# T113-S3 register map
Vendor: Allwinner; Series: T113-S3; File version: 0.1
CPU: other 0, little endian, MPU, no FPU, 0 interrupt priority bits
Registers are 32-bit, read-write, reset 0x0 unless marked. A register's access mark holds for its fields unless they carry their own. Offsets are from the block's base; [hi:lo] are bit positions; {n}, {i} and the like mark numbered series.

## CAN0
Base 0x02504000
Same registers: CAN1 0x02504400
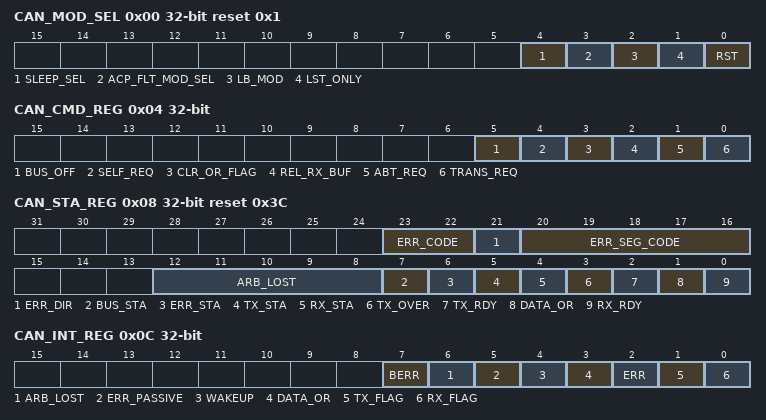
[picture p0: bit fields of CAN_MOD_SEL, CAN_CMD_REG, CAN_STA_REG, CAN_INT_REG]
0x00 CAN_MOD_SEL reset 0x1
  [4] SLEEP_SEL — Sleep Mode 0 : Wake-up (normal operation). If sleeping, the controller wakes up. 1: Sleep. The controller enters its Sleep Mode provided no CAN interrupt is pending and there is no bus activity (If there is bus activity or an interrupt is pending, the Wake-Up procedure is executed). Note: This bit can only be written in Operation Mode.
    1=Sleep. The controller enters its Sleep Mode provided no CAN interrupt is pending and there is no bus activity (If there is bus activity or an interrupt is pending, the Wake-Up procedure is executed). Note: This bit can only be written in Operation Mode.
  [3] ACP_FLT_MOD_SEL — Acceptance Filter Mode Select 0 : Dual Filter. Receive data filtered using two shorter filters. 1: Single Filter. Receive data MOD.3 AFM Acceptance Filter Mode1 filtered using one 4-byte filter.
    1=Single Filter. Receive data MOD.3 AFM Acceptance Filter Mode1 filtered using one 4-byte filter.
  [2] LB_MOD — Loopback Mode 0: Normal operation. An acknowledgement is required for successful transmission. 1: Self Test enabled. In this mode, a full node test is possible without any other active node on the bus using the self reception request command. The MCAN2 will perform a successful transmission, even if no acknowledge is received.
    0=Normal operation. An acknowledgement is required for successful transmission.; 1=Self Test enabled. In this mode, a full node test is possible without any other active node on the bus using the self reception request command. The MCAN2 will perform a successful transmission, even if no acknowledge is received.
  [1] LST_ONLY — Listen Only Mode 0: Normal operation. The error counters are stopped at the current value. 1: Listen Only enabled. In this mode, the controller does not send an acknowledge to the CAN bus, even when a message is received successfully.
    0=Normal operation. The error counters are stopped at the current value.; 1=Listen Only enabled. In this mode, the controller does not send an acknowledge to the CAN bus, even when a message is received successfully.
  [0] RST — Reset Mode 0: Normal operation. The controller returns to Operating Mode 1: Reset mode selected. Any message currently being transmitted or received is aborted and Reset Mode is entered.
    0=Normal operation. The controller returns to Operating Mode; 1=Reset mode selected. Any message currently being transmitted or received is aborted and Reset Mode is entered.
0x04 CAN_CMD_REG
  [5] BUS_OFF wo — Bus off Request Set this bit to 1 to initial a CPU-driven BUS OFF event.
  [4] SELF_REQ wo — Self Reception Request Set this bit to 1 to make a message to be transmitted and received simultaneously.
  [3] CLR_OR_FLAG wo — Clear Data Overrun Flag Set this bit to 1 to clear the data overrun flag signaled by the data overrun status bit. Note: No further data overrun interrupt will be generated while data overrun status bit remains set.
  [2] REL_RX_BUF wo — Release Rx Buffer Set this bit to 1 to release receive buffer.
  [1] ABT_REQ wo — Abort Request Set this bit to 1 to request to abort the current message transmission.
  [0] TRANS_REQ wo — Transmission Request Set this bit to 1 to request to transmit a message.
0x08 CAN_STA_REG reset 0x3C
  [23:22] ERR_CODE ro — Error Capture Error Code 00: Bit error 01: Form error 10: Stuff error 11: Some other type of error
    0=Bit (Bit error); 1=Form error; 2=Stuff error; 3=Some other type of error
  [21] ERR_DIR ro — Error Capture Direction 1: The error occurred during reception. 0 : The error occurred during transmission.
    1=error (The error occurred during reception. 0 : The error occurred during transmission.)
  [20:16] ERR_SEG_CODE ro — Error Capture Segment Code 00011: Start of frame 00010: ID.28 to ID.21 00110: ID.20 to ID.18 00100: SRTR bit 00101: IDE bit 00111: ID.17 to ID.13 01111: ID.12 to ID.5 01110: ID.4 to ID.0 01100: RTR bit 01101: Reserved bit 1 01001: Reserved bit 0 01011: Data Length Code 01010: Data Field 01000: CRC sequence 11000: CRC delimiter 11001: Acknowledge 11011: Acknowledge delimiter 11010: End of frame 10010: Intermission 10001: Active error flag 10110: Passive error flag 10011: Tolerate dominant bits 10111: Error delimiter 11100: Overload flag
  [12:8] ARB_LOST ro — Arbitration Lost Capture 00000~01010: Arbitration lost in bit[0~10](1 ~11 bit of ID, ID.28~ID.18). 01011: Arbitration lost in bit[11](SRTR bit ). 01100: Arbitration lost in bit[12](IDE bit ). 01101~11110: Arbitration lost in bit[13th~30th](12th~29th bit of ID, ID.17~ID.0). 11111: Arbitration lost in bit[31](RTR bit ).
    11=Arbitration_lost_in_bit[11]_openingparen_SRTR_bit (Arbitration lost in bit[11](SRTR bit ).); 12=Arbitration_lost_in_bit[12]_openingparen_IDE_bit (Arbitration lost in bit[12](IDE bit ). 01101~11110: Arbitration lost in bit[13th~30th](12th~29th bit of ID, ID.17~ID.0).); 31=Arbitration_lost_in_bit[31]_openingparen_RTR_bit (Arbitration lost in bit[31](RTR bit ).)
  [7] BUS_STA ro — Bus Status 0: The controller is involved in bus activities. 1: The controller is in `Bus Off` state and is not involved in bus activities.
    0=involved (The controller is involved in bus activities.); 1=in (The controller is in `Bus Off` state and is not involved in bus activities.)
  [6] ERR_STA ro — Error Status 0: Both error counters are below the warning limit. 1: At least one of the error counters has reached or exceeded the CPU warning limit defined by the Error Warning Limit Register (EWL).
    0=Both error counters are below the warning limit; 1=At (At least one of the error counters has reached or exceeded the CPU warning limit defined by the Error Warning Limit Register (EWL).)
  [5] TX_STA ro — Transmit Status 0: Nothing is currently being Transmitted. 1: Controller is in the process of transmitting a message.
    0=Nothing is currently being Transmitted; 1=Controller is in the process of transmitting a message
  [4] RX_STA ro — Receive Status 0: Nothing is currently being received. 1: Controller is in the process of receiving a message.
    0=Nothing is currently being received; 1=Controller is in the process of receiving a message
  [3] TX_OVER ro — Transmission Complete 0: The last requested transmission has not been completed. 1: The last requested transmission has been successfully completed.
    0=last_requested_transmission_has_not_been (The last requested transmission has not been completed.); 1=last_requested_transmission_has_been (The last requested transmission has been successfully completed.)
  [2] TX_RDY ro — Tx Buffer Ready 0: Tx buffer not ready. Transmit buffer is locked. The CPU cannot access the tx buffer. 1: Tx buffer ready. Transmit buffer is released. The CPU may write a message to transmit buffer.
    0=Tx buffer not ready. Transmit buffer is locked. The CPU cannot access the tx buffer.; 1=Tx buffer ready. Transmit buffer is released. The CPU may write a message to transmit buffer.
  [1] DATA_OR ro — Data overrun 0: Data buffer not overrun. 1: Data buffer overrun.
    0=Data_buffer_not_overrun; 1=Data_buffer_overrun
  [0] RX_RDY ro — Rx Buffer Ready 0: Rx buffer is empty. No message currently available to be read. 1: Rx buffer is not empty. One or more message are available to be read from Rx buffer.
    0=empty (Rx buffer is empty. No message currently available to be read.); 1=not_empty (Rx buffer is not empty. One or more message are available to be read from Rx buffer.)
0x0C CAN_INT_REG
  [7] BERR write-1-clears — Bus Error Interrupt Set when the controller detects an bit error on the CAN bus Note: This is a wirte-1-to-clear bit.
  [6] ARB_LOST write-1-clears — Arbitration Lost Interrupt Set when the controller loses arbitration and becomes a receiver Note: This is a wirte-1-to-clear bit.
  [5] ERR_PASSIVE write-1-clears — Error Passive Interrupt Set when the controller re-enters error active state after being in error passive state or when at least one error counter exceeds the protocol-defined level of 127. Note: This is a wirte-1-to-clear bit.
  [4] WAKEUP ro read-clears — Wake-Up Interrupt Set when bus activity is detected while the CAN controller is sleeping This is a read-to-clear bit.
  [3] DATA_OR write-1-clears — Data Overrun Interrupt Set on a `0-to-1` transition of the Data Overrun Status bit Note: This is a wirte-1-to-clear bit.
  [2] ERR write-1-clears — Error Warning Interrupt Set on every change (set or clear) of either the Bus Status or Error Status bits (SR.7,SR.6) Note: This is a wirte-1-to-clear bit.
  [1] TX_FLAG write-1-clears — Transmit Interrupt Flag Set whenever the Transmit Buffer Status (SR.2) changes from `0-to-1` (released) Note: This is a wirte-1-to-clear bit.
  [0] RX_FLAG write-1-clears — Receive Interrupt Flag Set whenever the Receive Buffer contains one or more messages. Cleared when the release Receive Buffer command (CMR. 2) is issued, provided there is no further data to read in the Receive Buffer. Note: This is a wirte-1-to-clear bit.
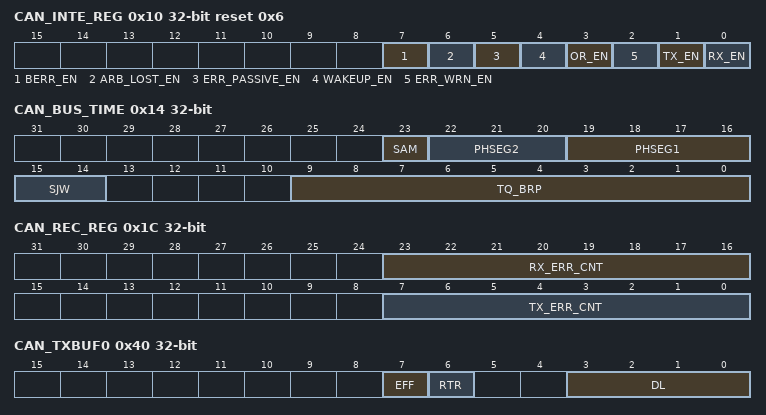
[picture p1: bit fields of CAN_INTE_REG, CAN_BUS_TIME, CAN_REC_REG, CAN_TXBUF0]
0x10 CAN_INTE_REG reset 0x6
  [7] BERR_EN — Bus Error Interrupt Enable 0: Bus error interrupt disable 1: Bus error interrupt enable
    0=Bus_error_interrupt_disable; 1=Bus_error_interrupt_enable
  [6] ARB_LOST_EN — Arbitration Lost Interrupt Enable 0: Arbitration lost interrupt disable 1: Arbitration lost interrupt enable
    0=Arbitration_lost_interrupt_disable; 1=Arbitration_lost_interrupt_enable
  [5] ERR_PASSIVE_EN — Error Passive Interrupt Enable 0: Error passive interrupt disable 1: Error passive interrupt enable
    0=Error_passive_interrupt_disable; 1=Error_passive_interrupt_enable
  [4] WAKEUP_EN — Wake-Up Interrupt Enable 0: Wake up interrupt disable 1: Wake up interrupt enable
    0=Wake_up_interrupt_disable; 1=Wake_up_interrupt_enable
  [3] OR_EN — Data Overrun Interrupt Enable 0: Data overrun interrupt disable 1: Data overrun interrupt enable
    0=Data_overrun_interrupt_disable; 1=Data_overrun_interrupt_enable
  [2] ERR_WRN_EN — Error Warning Interrupt Enable 0: Error Warning Interrupt disable 1: Error Warning Interrupt enable
    0=Error_Warning_Interrupt_disable; 1=Error_Warning_Interrupt_enable
  [1] TX_EN — Transmit Interrupt Enable 0: Transmit interrupt disable 1:Transmit interrupt enable
    0=Transmit interrupt disable 1:Transmit interrupt enable
  [0] RX_EN — Receive Interrupt Enable 0: Receive interrupt disable 1: Receive interrupt enable
    0=Receive_interrupt_disable; 1=Receive_interrupt_enable
0x14 CAN_BUS_TIME
  [23] SAM — Sample Point Control 0: Bus line is sampled once at the sample point 1: Bus line is sampled three times at the sample point Note: This bit is only writable in reset mode.
    0=sampled_once (Bus line is sampled once at the sample point); 1=sampled_three (Bus line is sampled three times at the sample point Note: This bit is only writable in reset mode.)
  [22:20] PHSEG2 — Phase Segment 2 [0..7] - [1..8] Tq clock cycle(s) Note: These bits are only writable in reset mode.
  [19:16] PHSEG1 — Phase Segment 1 [0..15] - [1..16] Tq clock cycle(s) Note: These bits are only writable in reset mode.
  [15:14] SJW — Synchronization Jump Width The SJW defines the maximum number of Tq clock cycles a bit can be shortened or lengthened to achieve resynchronization to data transitions on the bus. 00: 1 Tq clock cycle 01: 2 Tq clock cycles 10: 3 Tq clock cycles 11: 4 Tq clock cycles Note: These bits are only writable in reset mode.
    0=1 Tq clock cycle; 1=2 Tq clock cycles; 2=3 Tq clock cycles; 3=4 Tq clock cycles Note: These bits are only writable in reset mode
  [9:0] TQ_BRP — Time Quanta Baud Rate Prescaler These bits determine the time quanta (Tq)clock which is used to build up the individual bit timing. Note: These bits are only writable in reset mode.
0x18 CAN_EWL_REG reset 0x60
  [7:0] ERR_WRN_LMT — Error Warning Limit These bits define the number of errors after which an Error Warning Interrupt should be generated (if enabled). Note: These bits are only writable in reset mode.
0x1C CAN_REC_REG
  [23:16] RX_ERR_CNT — Receive Error Counter These bits record the current value of receive counter Note: These bits are only writable in reset mode.
  [7:0] TX_ERR_CNT — Transmit Error Counter These bits record the current value of transmit counter Note: These bits are only writable in reset mode.
0x20 CAN_RMSGC_REG
  [7:0] RX_MSG_CNT ro — CAN receive message counter
0x24 CAN_RSADDR_REG
  [5:0] RX_BUFF_SADDR — CAN receive buffer start address pointer Note: These bits are only writable in reset mode.
0x28 CAN_AC0_REG
  [31:0] CAN_ACP_CODE — CAN acceptance code byte[3:0]
0x2C CAN_AM0_REG
  [7:0] CAN_ACP_MSK — CAN acceptance mask byte[3:0]
0x40 CAN_TXBUF0
  [7] EFF — Extend frame flag 0: Standard frame 1: Extend frame
    0=Standard frame; 1=Extend frame
  [6] RTR — Remote Transmit 0: Normal frame 1: Remote frame
    0=Normal frame; 1=Remote frame
  [3:0] DL — Date length of message requested to send.
0x44 CAN_TXBUF1
  [7:0] ID — ID[28:21]
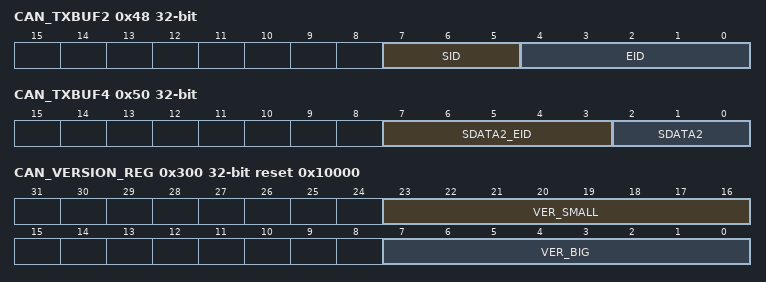
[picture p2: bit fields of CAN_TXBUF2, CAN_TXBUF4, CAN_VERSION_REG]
0x48 CAN_TXBUF2
  [7:5] SID — Standard ID SEF-ID[20:18] / EFF-ID[20:18]
  [4:0] EID — Extended ID EFF- ID[17:13]
0x4C CAN_TXBUF3
  [7:0] SDATA1_EID — SFF - TX data byte 1 / EFF- ID[12:5]
0x50 CAN_TXBUF4
  [7:3] SDATA2_EID — SFF-TX data byte2[7:3] / EFF-ID[4:0]
  [2:0] SDATA2 — SFF-TX data byte2[2:0]
{0x40+4i} CAN_TXBUF{i} (i=5..10)
  [7:0] SDATA{i-2}_EDATA{i-4} — SFF-TX data byte {i-2} / EFF-TX data byte {i-4}
0x6C CAN_TXBUF11
  [7:0] EDATA7 — EFF-TX data byte 7
0x70 CAN_TXBUF12
  [7:0] EDATA8 — EFF-TX data byte 8
{0x180+4i} CAN_WBUF_RD[{i}] (i=0..12) — CAN_WBUF_RD[{i}]
  [7:0] TBUF_RD_BACK ro — TX message buffer for read back Note: Each register is 32-bit width register, but only the lower 8 bit is valid to access. All higher 24 bit will return 0 when be read.
0x300 CAN_VERSION_REG reset 0x10000
  [23:16] VER_SMALL ro — Small Version of CAN hardware circuit
  [7:0] VER_BIG ro — Big Version of CAN hardware circuit
